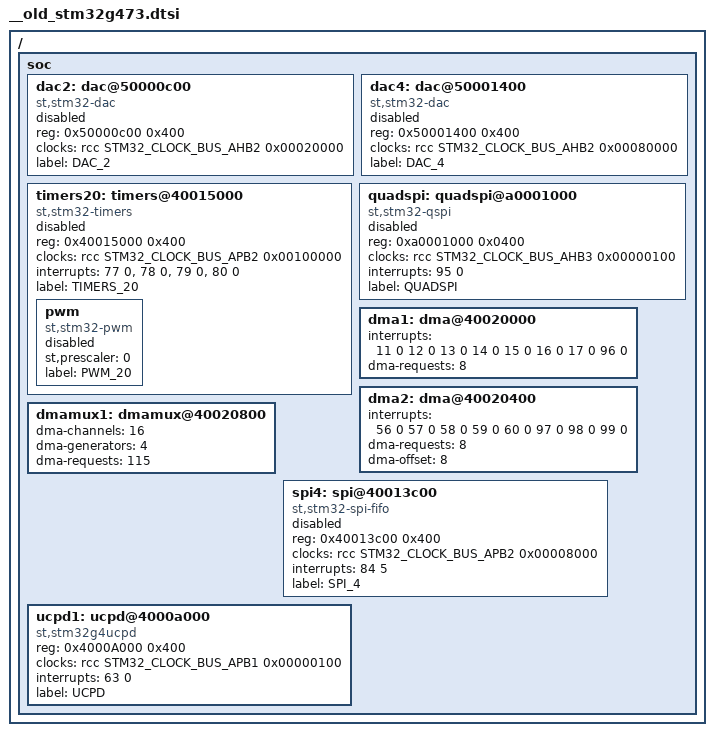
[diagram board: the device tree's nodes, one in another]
/*
 * Copyright (c) 2021 Acme CPU
 *
 * SPDX-License-Identifier: Apache-2.0
 */

#include <st/g4/stm32g4.dtsi>

/ {
	soc {

		dac2: dac@50000c00 {
			compatible = "st,stm32-dac";
			reg = <0x50000c00 0x400>;
			clocks = <&rcc STM32_CLOCK_BUS_AHB2 0x00020000>;
			status = "disabled";
			label = "DAC_2";
			#io-channel-cells = <1>;
		};

		dac4: dac@50001400 {
			compatible = "st,stm32-dac";
			reg = <0x50001400 0x400>;
			clocks = <&rcc STM32_CLOCK_BUS_AHB2 0x00080000>;
			status = "disabled";
			label = "DAC_4";
			#io-channel-cells = <1>;
		};
		
		timers20: timers@40015000 {
			compatible = "st,stm32-timers";
			reg = <0x40015000 0x400>;							/* RM0440 ref manual: Pg. 83, table 3 */
			clocks = <&rcc STM32_CLOCK_BUS_APB2 0x00100000>;	/* RM0440 ref manual: Pg. 316, sec. 7.4.19 */
			interrupts = <77 0>, <78 0>, <79 0>, <80 0>;		/* RM0440 ref manual: Pg. 445, table 97 */
			interrupt-names = "brk", "up", "trgcom", "cc";
			status = "disabled";
			label = "TIMERS_20";

			pwm {
				compatible = "st,stm32-pwm";
				status = "disabled";
				st,prescaler = <0>;
				label = "PWM_20";
				#pwm-cells = <3>;
			};
		};
		
		quadspi: quadspi@a0001000 {
			compatible = "st,stm32-qspi";
			#address-cells = <1>;
			#size-cells = <0>;
			reg = <0xa0001000 0x0400>;							/* RM0440 ref manual: Pg. 82, table 3 */
			clocks = <&rcc STM32_CLOCK_BUS_AHB3 0x00000100>;	
			interrupts = <95 0>;								/* RM0440 ref manual: Pg. 445, table 97 */
			status = "disabled";
			label = "QUADSPI";
		};
		
		/* dma1, dma2, dmamux1 and spi4 are borrowed from stm32g474.dtsi file inside zephyr */
		dma1: dma@40020000 {
			status = "okay";
			interrupts = <11 0 12 0 13 0 14 0 15 0 16 0 17 0 96 0>;
			dma-requests = <8>;
		};

		dma2: dma@40020400 {
			status = "okay";
			interrupts = <56 0 57 0 58 0 59 0 60 0 97 0 98 0 99 0>;
			dma-requests = <8>;
			dma-offset = <8>;
		};

		dmamux1: dmamux@40020800 {
			status = "okay";
			dma-channels = <16>;
			dma-generators = <4>;
			dma-requests= <115>;
		};

		spi4: spi@40013c00 {
			compatible = "st,stm32-spi-fifo", "st,stm32-spi";
			#address-cells = <1>;
			#size-cells = <0>;
			reg = <0x40013c00 0x400>;
			clocks = <&rcc STM32_CLOCK_BUS_APB2 0x00008000>;
			interrupts = <84 5>;
			status = "disabled";
			label = "SPI_4";
		};
		
		ucpd1: ucpd@4000a000 {
			compatible = "st,stm32g4ucpd";
			#address-cells = <1>;
			#size-cells = <0>;
			reg = <0x4000A000 0x400>;							/* RM0440 ref manual: Pg. 84, table 3 */
			clocks = <&rcc STM32_CLOCK_BUS_APB1 0x00000100>;	/* RM0440 ref manual: Pg. 314, sec. 7.4.18 */
			interrupts = <63 0>;								/* RM0440 ref manual: Pg. 444, table 97 */
			interrupt-names = "global";
			status = "okay";
			label = "UCPD";
		};
	};
};
